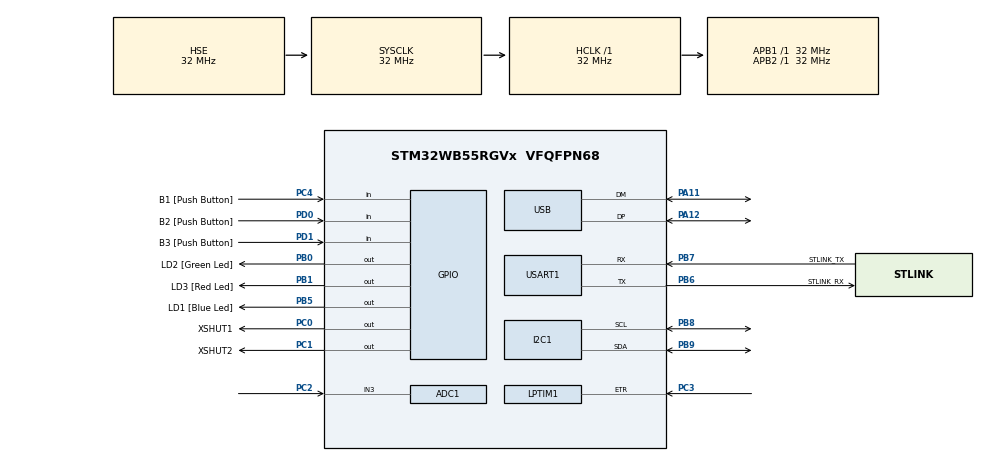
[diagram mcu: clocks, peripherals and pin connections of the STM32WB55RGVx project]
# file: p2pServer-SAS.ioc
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ADC1.Channel-0\#ChannelRegularConversion=ADC_CHANNEL_3
ADC1.Channel-1\#ChannelRegularConversion=ADC_CHANNEL_VREFINT
ADC1.ContinuousConvMode=ENABLE
ADC1.NbrOfConversion=2
ADC1.NbrOfConversionFlag=1
ADC1.OffsetNumber-0\#ChannelRegularConversion=ADC_OFFSET_NONE
ADC1.OffsetNumber-1\#ChannelRegularConversion=ADC_OFFSET_NONE
ADC1.Rank-0\#ChannelRegularConversion=1
ADC1.Rank-1\#ChannelRegularConversion=2
ADC1.SamplingTime-0\#ChannelRegularConversion=ADC_SAMPLETIME_247CYCLES_5
ADC1.SamplingTime-1\#ChannelRegularConversion=ADC_SAMPLETIME_247CYCLES_5
ADC1.master=1
Dma.ADC1.0.Direction=DMA_PERIPH_TO_MEMORY
Dma.ADC1.0.EventEnable=DISABLE
Dma.ADC1.0.Instance=DMA1_Channel1
Dma.ADC1.0.MemDataAlignment=DMA_MDATAALIGN_HALFWORD
Dma.ADC1.0.MemInc=DMA_MINC_ENABLE
Dma.ADC1.0.Mode=DMA_CIRCULAR
Dma.ADC1.0.PeriphDataAlignment=DMA_PDATAALIGN_HALFWORD
Dma.ADC1.0.PeriphInc=DMA_PINC_DISABLE
Dma.ADC1.0.Polarity=HAL_DMAMUX_REQ_GEN_RISING
Dma.ADC1.0.Priority=DMA_PRIORITY_MEDIUM
Dma.ADC1.0.RequestNumber=1
Dma.ADC1.0.SignalID=NONE
Dma.ADC1.0.SyncEnable=DISABLE
Dma.ADC1.0.SyncPolarity=HAL_DMAMUX_SYNC_NO_EVENT
Dma.ADC1.0.SyncRequestNumber=1
Dma.ADC1.0.SyncSignalID=NONE
Dma.Request0=ADC1
Dma.Request1=USART1_TX
Dma.USART1_TX.1.Direction=DMA_MEMORY_TO_PERIPH
Dma.USART1_TX.1.EventEnable=DISABLE
Dma.USART1_TX.1.Instance=DMA2_Channel4
Dma.USART1_TX.1.MemDataAlignment=DMA_MDATAALIGN_BYTE
Dma.USART1_TX.1.MemInc=DMA_MINC_ENABLE
Dma.USART1_TX.1.Mode=DMA_NORMAL
Dma.USART1_TX.1.PeriphDataAlignment=DMA_PDATAALIGN_BYTE
Dma.USART1_TX.1.PeriphInc=DMA_PINC_DISABLE
Dma.USART1_TX.1.Polarity=HAL_DMAMUX_REQ_GEN_RISING
Dma.USART1_TX.1.Priority=DMA_PRIORITY_LOW
Dma.USART1_TX.1.RequestNumber=1
Dma.USART1_TX.1.SignalID=NONE
Dma.USART1_TX.1.SyncEnable=DISABLE
Dma.USART1_TX.1.SyncPolarity=HAL_DMAMUX_SYNC_NO_EVENT
Dma.USART1_TX.1.SyncRequestNumber=1
Dma.USART1_TX.1.SyncSignalID=NONE
I2C1.Timing=0x00707CBB
LPTIM1.ClockPrescaler=LPTIM_PRESCALER_DIV128
Mcu.Family=STM32WB
Mcu.Name=STM32WB55RGVx
Mcu.Package=VFQFPN68
NVIC.ADC1_IRQn=true\:0\:0\:false\:false\:true\:true\:true
NVIC.DMA1_Channel1_IRQn=true\:0\:0\:false\:false\:true\:false\:true
NVIC.DMA2_Channel4_IRQn=true\:0\:0\:false\:false\:true\:false\:true
NVIC.HSEM_IRQn=true\:0\:0\:false\:false\:true\:false\:true
NVIC.LPTIM1_IRQn=true\:0\:0\:false\:false\:true\:true\:true
NVIC.PriorityGroup=NVIC_PRIORITYGROUP_4
NVIC.TIM1_UP_TIM16_IRQn=true\:0\:0\:false\:false\:true\:true\:true
NVIC.USB_LP_IRQn=true\:0\:0\:false\:false\:true\:false\:true
OSC_IN.Mode=HSE-External-Oscillator
OSC_IN.Signal=RCC_OSC_IN
OSC_OUT.Mode=HSE-External-Oscillator
OSC_OUT.Signal=RCC_OSC_OUT
PA11.Mode=Device
PA11.Signal=USB_DM
PA12.Mode=Device
PA12.Signal=USB_DP
PA13.GPIO_Label=JTMS
PA13.Mode=Trace_Asynchronous_SW
PA13.Signal=SYS_JTMS-SWDIO
PA14.GPIO_Label=JTCK
PA14.Mode=Trace_Asynchronous_SW
PA14.Signal=SYS_JTCK-SWCLK
PB0.GPIO_Label=LD2 [Green Led]
PB0.Signal=GPIO_Output
PB1.GPIO_Label=LD3 [Red Led]
PB1.Signal=GPIO_Output
PB3.GPIO_Label=JTDO
PB3.Mode=Trace_Asynchronous_SW
PB3.Signal=SYS_JTDO-SWO
PB5.GPIO_Label=LD1 [Blue Led]
PB5.Signal=GPIO_Output
PB6.GPIO_Label=STLINK_RX
PB6.GPIO_PuPd=GPIO_PULLUP
PB6.Mode=Asynchronous
PB6.Signal=USART1_TX
PB7.GPIO_Label=STLINK_TX
PB7.GPIO_PuPd=GPIO_PULLUP
PB7.Mode=Asynchronous
PB7.Signal=USART1_RX
PB8.Mode=I2C
PB8.Signal=I2C1_SCL
PB9.Mode=I2C
PB9.Signal=I2C1_SDA
PC0.GPIO_Label=XSHUT1
PC0.Signal=GPIO_Output
PC1.GPIO_Label=XSHUT2
PC1.Signal=GPIO_Output
PC13.Mode=SYS_WakeUp1
PC13.Signal=SYS_WKUP2
PC14-OSC32_IN.Mode=LSE-External-Oscillator
PC14-OSC32_IN.Signal=RCC_OSC32_IN
PC15-OSC32_OUT.Mode=LSE-External-Oscillator
PC15-OSC32_OUT.Signal=RCC_OSC32_OUT
PC2.Signal=ADCx_IN3
PC3.Mode=ExternalTrigger
PC3.Signal=LPTIM1_ETR
PC4.GPIO_Label=B1 [Push Button]
PC4.Signal=GPIO_Input
PD0.GPIO_Label=B2 [Push Button]
PD0.Signal=GPIO_Input
PD1.GPIO_Label=B3 [Push Button]
PD1.Signal=GPIO_Input
ProjectManager.HeapSize=0x200
ProjectManager.StackSize=0x400
ProjectManager.TargetToolchain=MDK-ARM V5.32
RCC.ADCFreq_Value=12000000
RCC.AHBFreq_Value=32000000
RCC.APB1Freq_Value=32000000
RCC.APB1TimFreq_Value=32000000
RCC.APB2Freq_Value=32000000
RCC.APB2TimFreq_Value=32000000
RCC.APB3Freq_Value=16000000
RCC.CortexFreq_Value=32000000
RCC.HCLKFreq_Value=32000000
RCC.HSE_VALUE=32000000
RCC.HSI48_VALUE=48000000
RCC.HSI_VALUE=16000000
RCC.PLLN=32
RCC.PLLSAI1N=24
RCC.PLLSAI1R=RCC_PLLR_DIV8
RCC.RFWKPClockSelection=RCC_RFWKPCLKSOURCE_LSE
RCC.SMPSCLockSelectionVirtual=RCC_SMPSCLKSOURCE_HSI
RCC.SMPSCLockSelectionVirtualVirtual=RCC_SMPSCLKSOURCE_HSI
RCC.SMPSDivider=1
RCC.SYSCLKFreq_VALUE=32000000
RCC.SYSCLKSource=RCC_SYSCLKSOURCE_HSE
RCC.USBFreq_Value=48000000
RCC.VCOOutputFreq_Value=128000000
RF1.Mode=RF1_Activate
RF1.Signal=RF_RF1
SH.ADCx_IN3.0=ADC1_IN3,IN3-Single-Ended
STM32_WPAN.CFG_DEBUGGER_SUPPORTED=1
STM32_WPAN.CFG_DEBUG_APP_TRACE=1
STM32_WPAN.CFG_DEBUG_BLE_TRACE=1
STM32_WPAN.CFG_DEBUG_TRACE_UART=hw_uart1
STM32_WPAN.CFG_HW_USART1_ENABLED=0
STM32_WPAN.CFG_LPM_SUPPORTED=1
STM32_WPAN.CUSTOM_P2P_SERVER=Enabled
STM32_WPAN.LOCAL_NAME=SAS_v1
STM32_WPAN.LOCAL_NAME_FORMATTED=,'S','A','S','_','v','1'
STM32_WPAN.P2P_SERVER_NUMBER=P2P_SERVER1
TIM1.Period=2000
TIM1.Prescaler=31999
USART1.VirtualMode-Asynchronous=VM_ASYNC
USART1.WordLength=WORDLENGTH_7B
USB_DEVICE.CLASS_NAME_FS=CDC
USB_DEVICE.VirtualMode=Cdc
USB_DEVICE.VirtualModeFS=Cdc_FS
VP_ADC1_Vref_Input.Mode=IN-Vrefint
VP_HSEM_VS_HSEM.Mode=HSEM_Activate
VP_IPCC_VS_IPCC.Mode=IPCC_Activate
VP_LPTIM1_VS_LPTIM_counterModeInternalClock.Mode=Counts__internal_clock_event_00
VP_RTC_VS_RTC_Activate.Mode=RTC_Enabled
VP_SEQUENCER_VS_SEQUENCER.Mode=SEQUENCER_Enabled
VP_STM32_WPAN_VS_BLE_HOST.Mode=STM32_WPAN_Enabled
VP_TIM1_VS_ClockSourceINT.Mode=Internal
VP_TINY_LPM_VS_TINY_LPM.Mode=TINY_LPM_Enabled
VP_USB_DEVICE_VS_USB_DEVICE_CDC_FS.Mode=CDC_FS
board=NUCLEO-WB55RG

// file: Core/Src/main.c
/* USER CODE BEGIN Header */
/**
  ******************************************************************************
  * @file           : main.c
  * @brief          : Main program body
  ******************************************************************************
  * @attention
  *
  * <h2><center>&copy; Copyright (c) 2021 STMicroelectronics.
  * All rights reserved.</center></h2>
  *
  * This software component is licensed by ST under Ultimate Liberty license
  * SLA0044, the "License"; You may not use this file except in compliance with
  * the License. You may obtain a copy of the License at:
  *                             www.st.com/SLA0044
  *
  ******************************************************************************
  */
/* USER CODE END Header */
#include "main.h"
#include "usb_device.h"

/* USER CODE BEGIN Includes */
#include "stm32_seq.h"
/* USER CODE END Includes */

ADC_HandleTypeDef hadc1;
DMA_HandleTypeDef hdma_adc1;

I2C_HandleTypeDef hi2c1;

IPCC_HandleTypeDef hipcc;

LPTIM_HandleTypeDef hlptim1;

RTC_HandleTypeDef hrtc;

TIM_HandleTypeDef htim1;

UART_HandleTypeDef huart1;
DMA_HandleTypeDef hdma_usart1_tx;

/* USER CODE BEGIN PV */
volatile uint8_t DMA_flag = 0;
volatile float battery_voltage = 0;
volatile float mcu_voltage = 0;
uint32_t ADC_buffer[2] = {0,};
/* USER CODE END PV */

void SystemClock_Config(void);
static void MX_GPIO_Init(void);
static void MX_I2C1_Init(void);
static void MX_IPCC_Init(void);
static void MX_RF_Init(void);
static void MX_RTC_Init(void);
static void MX_USART1_UART_Init(void);
static void MX_DMA_Init(void);
static void MX_ADC1_Init(void);
static void MX_TIM1_Init(void);
static void MX_LPTIM1_Init(void);

int main(void)
{

  /* MCU Configuration--------------------------------------------------------*/

  /* Reset of all peripherals, Initializes the Flash interface and the Systick. */
  HAL_Init();
  /* Config code for STM32_WPAN (HSE Tuning must be done before system clock configuration) */
  MX_APPE_Config();

  /* Configure the system clock */
  SystemClock_Config();

  /* IPCC initialisation */
   MX_IPCC_Init();

  /* Initialize all configured peripherals */
  MX_GPIO_Init();
  MX_I2C1_Init();
  MX_RF_Init();
  MX_RTC_Init();
  MX_USART1_UART_Init();
  MX_DMA_Init();
  MX_ADC1_Init();
  MX_TIM1_Init();
  MX_USB_Device_Init();
  MX_LPTIM1_Init();

  /* Init code for STM32_WPAN */
  MX_APPE_Init();
  /* Infinite loop */
  while (1)
  {
    MX_APPE_Process();

  }
}

void SystemClock_Config(void)
{
  RCC_OscInitTypeDef RCC_OscInitStruct = {0};
  RCC_ClkInitTypeDef RCC_ClkInitStruct = {0};
  RCC_PeriphCLKInitTypeDef PeriphClkInitStruct = {0};

  /** Macro to configure the PLL multiplication factor
  */
  __HAL_RCC_PLL_PLLM_CONFIG(RCC_PLLM_DIV1);
  /** Macro to configure the PLL clock source
  */
  __HAL_RCC_PLL_PLLSOURCE_CONFIG(RCC_PLLSOURCE_MSI);
  /** Configure LSE Drive Capability
  */
  HAL_PWR_EnableBkUpAccess();
  __HAL_RCC_LSEDRIVE_CONFIG(RCC_LSEDRIVE_LOW);
  /** Configure the main internal regulator output voltage
  */
  __HAL_PWR_VOLTAGESCALING_CONFIG(PWR_REGULATOR_VOLTAGE_SCALE1);
  /** Initializes the RCC Oscillators according to the specified parameters
  * in the RCC_OscInitTypeDef structure.
  */
  RCC_OscInitStruct.OscillatorType = RCC_OSCILLATORTYPE_HSI|RCC_OSCILLATORTYPE_LSI1
                              |RCC_OSCILLATORTYPE_HSE|RCC_OSCILLATORTYPE_LSE
                              |RCC_OSCILLATORTYPE_MSI;
  RCC_OscInitStruct.HSEState = RCC_HSE_ON;
  RCC_OscInitStruct.LSEState = RCC_LSE_ON;
  RCC_OscInitStruct.HSIState = RCC_HSI_ON;
  RCC_OscInitStruct.MSIState = RCC_MSI_ON;
  RCC_OscInitStruct.HSICalibrationValue = RCC_HSICALIBRATION_DEFAULT;
  RCC_OscInitStruct.MSICalibrationValue = RCC_MSICALIBRATION_DEFAULT;
  RCC_OscInitStruct.MSIClockRange = RCC_MSIRANGE_6;
  RCC_OscInitStruct.LSIState = RCC_LSI_ON;
  RCC_OscInitStruct.PLL.PLLState = RCC_PLL_NONE;
  if (HAL_RCC_OscConfig(&RCC_OscInitStruct) != HAL_OK)
  {
    Error_Handler();
  }
  /** Configure the SYSCLKSource, HCLK, PCLK1 and PCLK2 clocks dividers
  */
  RCC_ClkInitStruct.ClockType = RCC_CLOCKTYPE_HCLK4|RCC_CLOCKTYPE_HCLK2
                              |RCC_CLOCKTYPE_HCLK|RCC_CLOCKTYPE_SYSCLK
                              |RCC_CLOCKTYPE_PCLK1|RCC_CLOCKTYPE_PCLK2;
  RCC_ClkInitStruct.SYSCLKSource = RCC_SYSCLKSOURCE_HSE;
  RCC_ClkInitStruct.AHBCLKDivider = RCC_SYSCLK_DIV1;
  RCC_ClkInitStruct.APB1CLKDivider = RCC_HCLK_DIV1;
  RCC_ClkInitStruct.APB2CLKDivider = RCC_HCLK_DIV1;
  RCC_ClkInitStruct.AHBCLK2Divider = RCC_SYSCLK_DIV1;
  RCC_ClkInitStruct.AHBCLK4Divider = RCC_SYSCLK_DIV1;

  if (HAL_RCC_ClockConfig(&RCC_ClkInitStruct, FLASH_LATENCY_1) != HAL_OK)
  {
    Error_Handler();
  }
  /** Initializes the peripherals clocks
  */
  PeriphClkInitStruct.PeriphClockSelection = RCC_PERIPHCLK_SMPS|RCC_PERIPHCLK_RFWAKEUP
                              |RCC_PERIPHCLK_RTC|RCC_PERIPHCLK_USART1
                              |RCC_PERIPHCLK_LPTIM1|RCC_PERIPHCLK_I2C1
                              |RCC_PERIPHCLK_USB|RCC_PERIPHCLK_ADC;
  PeriphClkInitStruct.PLLSAI1.PLLN = 24;
  PeriphClkInitStruct.PLLSAI1.PLLP = RCC_PLLP_DIV2;
  PeriphClkInitStruct.PLLSAI1.PLLQ = RCC_PLLQ_DIV2;
  PeriphClkInitStruct.PLLSAI1.PLLR = RCC_PLLR_DIV8;
  PeriphClkInitStruct.PLLSAI1.PLLSAI1ClockOut = RCC_PLLSAI1_USBCLK|RCC_PLLSAI1_ADCCLK;
  PeriphClkInitStruct.Usart1ClockSelection = RCC_USART1CLKSOURCE_PCLK2;
  PeriphClkInitStruct.I2c1ClockSelection = RCC_I2C1CLKSOURCE_PCLK1;
  PeriphClkInitStruct.Lptim1ClockSelection = RCC_LPTIM1CLKSOURCE_PCLK1;
  PeriphClkInitStruct.UsbClockSelection = RCC_USBCLKSOURCE_PLLSAI1;
  PeriphClkInitStruct.AdcClockSelection = RCC_ADCCLKSOURCE_PLLSAI1;
  PeriphClkInitStruct.RTCClockSelection = RCC_RTCCLKSOURCE_LSI;
  PeriphClkInitStruct.RFWakeUpClockSelection = RCC_RFWKPCLKSOURCE_LSE;
  PeriphClkInitStruct.SmpsClockSelection = RCC_SMPSCLKSOURCE_HSI;
  PeriphClkInitStruct.SmpsDivSelection = RCC_SMPSCLKDIV_RANGE0;
  if (HAL_RCCEx_PeriphCLKConfig(&PeriphClkInitStruct) != HAL_OK)
  {
    Error_Handler();
  }
  /** Enable MSI Auto calibration
  */
  HAL_RCCEx_EnableMSIPLLMode();
}

static void MX_ADC1_Init(void)
{

  ADC_ChannelConfTypeDef sConfig = {0};

  /** Common config
  */
  hadc1.Instance = ADC1;
  hadc1.Init.ClockPrescaler = ADC_CLOCK_ASYNC_DIV1;
  hadc1.Init.Resolution = ADC_RESOLUTION_12B;
  hadc1.Init.DataAlign = ADC_DATAALIGN_RIGHT;
  hadc1.Init.ScanConvMode = ADC_SCAN_ENABLE;
  hadc1.Init.EOCSelection = ADC_EOC_SINGLE_CONV;
  hadc1.Init.LowPowerAutoWait = DISABLE;
  hadc1.Init.ContinuousConvMode = ENABLE;
  hadc1.Init.NbrOfConversion = 2;
  hadc1.Init.DiscontinuousConvMode = DISABLE;
  hadc1.Init.ExternalTrigConv = ADC_SOFTWARE_START;
  hadc1.Init.ExternalTrigConvEdge = ADC_EXTERNALTRIGCONVEDGE_NONE;
  hadc1.Init.DMAContinuousRequests = DISABLE;
  hadc1.Init.Overrun = ADC_OVR_DATA_PRESERVED;
  hadc1.Init.OversamplingMode = DISABLE;
  if (HAL_ADC_Init(&hadc1) != HAL_OK)
  {
    Error_Handler();
  }
  /** Configure Regular Channel
  */
  sConfig.Channel = ADC_CHANNEL_3;
  sConfig.Rank = ADC_REGULAR_RANK_1;
  sConfig.SamplingTime = ADC_SAMPLETIME_247CYCLES_5;
  sConfig.SingleDiff = ADC_SINGLE_ENDED;
  sConfig.OffsetNumber = ADC_OFFSET_NONE;
  sConfig.Offset = 0;
  if (HAL_ADC_ConfigChannel(&hadc1, &sConfig) != HAL_OK)
  {
    Error_Handler();
  }
  /** Configure Regular Channel
  */
  sConfig.Channel = ADC_CHANNEL_VREFINT;
  sConfig.Rank = ADC_REGULAR_RANK_2;
  if (HAL_ADC_ConfigChannel(&hadc1, &sConfig) != HAL_OK)
  {
    Error_Handler();
  }

}

static void MX_I2C1_Init(void)
{

  hi2c1.Instance = I2C1;
  hi2c1.Init.Timing = 0x00707CBB;
  hi2c1.Init.OwnAddress1 = 0;
  hi2c1.Init.AddressingMode = I2C_ADDRESSINGMODE_7BIT;
  hi2c1.Init.DualAddressMode = I2C_DUALADDRESS_DISABLE;
  hi2c1.Init.OwnAddress2 = 0;
  hi2c1.Init.OwnAddress2Masks = I2C_OA2_NOMASK;
  hi2c1.Init.GeneralCallMode = I2C_GENERALCALL_DISABLE;
  hi2c1.Init.NoStretchMode = I2C_NOSTRETCH_DISABLE;
  if (HAL_I2C_Init(&hi2c1) != HAL_OK)
  {
    Error_Handler();
  }
  /** Configure Analogue filter
  */
  if (HAL_I2CEx_ConfigAnalogFilter(&hi2c1, I2C_ANALOGFILTER_ENABLE) != HAL_OK)
  {
    Error_Handler();
  }
  /** Configure Digital filter
  */
  if (HAL_I2CEx_ConfigDigitalFilter(&hi2c1, 0) != HAL_OK)
  {
    Error_Handler();
  }

}

static void MX_IPCC_Init(void)
{

  hipcc.Instance = IPCC;
  if (HAL_IPCC_Init(&hipcc) != HAL_OK)
  {
    Error_Handler();
  }

}

static void MX_LPTIM1_Init(void)
{

  hlptim1.Instance = LPTIM1;
  hlptim1.Init.Clock.Source = LPTIM_CLOCKSOURCE_APBCLOCK_LPOSC;
  hlptim1.Init.Clock.Prescaler = LPTIM_PRESCALER_DIV128;
  hlptim1.Init.Trigger.Source = LPTIM_TRIGSOURCE_0;
  hlptim1.Init.Trigger.ActiveEdge = LPTIM_ACTIVEEDGE_RISING;
  hlptim1.Init.Trigger.SampleTime = LPTIM_TRIGSAMPLETIME_DIRECTTRANSITION;
  hlptim1.Init.OutputPolarity = LPTIM_OUTPUTPOLARITY_HIGH;
  hlptim1.Init.UpdateMode = LPTIM_UPDATE_IMMEDIATE;
  hlptim1.Init.CounterSource = LPTIM_COUNTERSOURCE_INTERNAL;
  hlptim1.Init.Input1Source = LPTIM_INPUT1SOURCE_GPIO;
  hlptim1.Init.Input2Source = LPTIM_INPUT2SOURCE_GPIO;
  if (HAL_LPTIM_Init(&hlptim1) != HAL_OK)
  {
    Error_Handler();
  }

}

static void MX_RF_Init(void)
{

}

static void MX_RTC_Init(void)
{

  /** Initialize RTC Only
  */
  hrtc.Instance = RTC;
  hrtc.Init.HourFormat = RTC_HOURFORMAT_24;
  hrtc.Init.AsynchPrediv = CFG_RTC_ASYNCH_PRESCALER;
  hrtc.Init.SynchPrediv = CFG_RTC_SYNCH_PRESCALER;
  hrtc.Init.OutPut = RTC_OUTPUT_DISABLE;
  hrtc.Init.OutPutPolarity = RTC_OUTPUT_POLARITY_HIGH;
  hrtc.Init.OutPutType = RTC_OUTPUT_TYPE_OPENDRAIN;
  hrtc.Init.OutPutRemap = RTC_OUTPUT_REMAP_NONE;
  if (HAL_RTC_Init(&hrtc) != HAL_OK)
  {
    Error_Handler();
  }

}

static void MX_TIM1_Init(void)
{

  TIM_ClockConfigTypeDef sClockSourceConfig = {0};
  TIM_MasterConfigTypeDef sMasterConfig = {0};

  htim1.Instance = TIM1;
  htim1.Init.Prescaler = 31999;
  htim1.Init.CounterMode = TIM_COUNTERMODE_UP;
  htim1.Init.Period = 2000;
  htim1.Init.ClockDivision = TIM_CLOCKDIVISION_DIV1;
  htim1.Init.RepetitionCounter = 0;
  htim1.Init.AutoReloadPreload = TIM_AUTORELOAD_PRELOAD_DISABLE;
  if (HAL_TIM_Base_Init(&htim1) != HAL_OK)
  {
    Error_Handler();
  }
  sClockSourceConfig.ClockSource = TIM_CLOCKSOURCE_INTERNAL;
  if (HAL_TIM_ConfigClockSource(&htim1, &sClockSourceConfig) != HAL_OK)
  {
    Error_Handler();
  }
  sMasterConfig.MasterOutputTrigger = TIM_TRGO_RESET;
  sMasterConfig.MasterOutputTrigger2 = TIM_TRGO2_RESET;
  sMasterConfig.MasterSlaveMode = TIM_MASTERSLAVEMODE_DISABLE;
  if (HAL_TIMEx_MasterConfigSynchronization(&htim1, &sMasterConfig) != HAL_OK)
  {
    Error_Handler();
  }

}

static void MX_USART1_UART_Init(void)
{

  huart1.Instance = USART1;
  huart1.Init.BaudRate = 115200;
  huart1.Init.WordLength = UART_WORDLENGTH_7B;
  huart1.Init.StopBits = UART_STOPBITS_1;
  huart1.Init.Parity = UART_PARITY_NONE;
  huart1.Init.Mode = UART_MODE_TX_RX;
  huart1.Init.HwFlowCtl = UART_HWCONTROL_NONE;
  huart1.Init.OverSampling = UART_OVERSAMPLING_16;
  huart1.Init.OneBitSampling = UART_ONE_BIT_SAMPLE_DISABLE;
  huart1.Init.ClockPrescaler = UART_PRESCALER_DIV1;
  huart1.AdvancedInit.AdvFeatureInit = UART_ADVFEATURE_NO_INIT;
  if (HAL_UART_Init(&huart1) != HAL_OK)
  {
    Error_Handler();
  }
  if (HAL_UARTEx_SetTxFifoThreshold(&huart1, UART_TXFIFO_THRESHOLD_1_8) != HAL_OK)
  {
    Error_Handler();
  }
  if (HAL_UARTEx_SetRxFifoThreshold(&huart1, UART_RXFIFO_THRESHOLD_1_8) != HAL_OK)
  {
    Error_Handler();
  }
  if (HAL_UARTEx_DisableFifoMode(&huart1) != HAL_OK)
  {
    Error_Handler();
  }

}

static void MX_DMA_Init(void)
{

  /* DMA controller clock enable */
  __HAL_RCC_DMAMUX1_CLK_ENABLE();
  __HAL_RCC_DMA1_CLK_ENABLE();
  __HAL_RCC_DMA2_CLK_ENABLE();

  /* DMA interrupt init */
  /* DMA1_Channel1_IRQn interrupt configuration */
  HAL_NVIC_SetPriority(DMA1_Channel1_IRQn, 0, 0);
  HAL_NVIC_EnableIRQ(DMA1_Channel1_IRQn);
  /* DMA2_Channel4_IRQn interrupt configuration */
  HAL_NVIC_SetPriority(DMA2_Channel4_IRQn, 0, 0);
  HAL_NVIC_EnableIRQ(DMA2_Channel4_IRQn);

}

static void MX_GPIO_Init(void)
{
  GPIO_InitTypeDef GPIO_InitStruct = {0};

  /* GPIO Ports Clock Enable */
  __HAL_RCC_GPIOC_CLK_ENABLE();
  __HAL_RCC_GPIOH_CLK_ENABLE();
  __HAL_RCC_GPIOB_CLK_ENABLE();
  __HAL_RCC_GPIOA_CLK_ENABLE();
  __HAL_RCC_GPIOE_CLK_ENABLE();
  __HAL_RCC_GPIOD_CLK_ENABLE();

  /*Configure GPIO pin Output Level */
  HAL_GPIO_WritePin(GPIOC, XSHUT1_Pin|XSHUT2_Pin, GPIO_PIN_RESET);

  /*Configure GPIO pin Output Level */
  HAL_GPIO_WritePin(GPIOB, LD2_Pin|LD3_Pin|LD1_Pin, GPIO_PIN_RESET);

  /*Configure GPIO pin : PH3 */
  GPIO_InitStruct.Pin = GPIO_PIN_3;
  GPIO_InitStruct.Mode = GPIO_MODE_ANALOG;
  GPIO_InitStruct.Pull = GPIO_NOPULL;
  HAL_GPIO_Init(GPIOH, &GPIO_InitStruct);

  /*Configure GPIO pins : XSHUT1_Pin XSHUT2_Pin */
  GPIO_InitStruct.Pin = XSHUT1_Pin|XSHUT2_Pin;
  GPIO_InitStruct.Mode = GPIO_MODE_OUTPUT_PP;
  GPIO_InitStruct.Pull = GPIO_NOPULL;
  GPIO_InitStruct.Speed = GPIO_SPEED_FREQ_LOW;
  HAL_GPIO_Init(GPIOC, &GPIO_InitStruct);

  /*Configure GPIO pins : PA0 PA1 PA2 PA3
                           PA4 PA5 PA6 PA7
                           PA8 PA9 PA10 PA15 */
  GPIO_InitStruct.Pin = GPIO_PIN_0|GPIO_PIN_1|GPIO_PIN_2|GPIO_PIN_3
                          |GPIO_PIN_4|GPIO_PIN_5|GPIO_PIN_6|GPIO_PIN_7
                          |GPIO_PIN_8|GPIO_PIN_9|GPIO_PIN_10|GPIO_PIN_15;
  GPIO_InitStruct.Mode = GPIO_MODE_ANALOG;
  GPIO_InitStruct.Pull = GPIO_NOPULL;
  HAL_GPIO_Init(GPIOA, &GPIO_InitStruct);

  /*Configure GPIO pin : B1_Pin */
  GPIO_InitStruct.Pin = B1_Pin;
  GPIO_InitStruct.Mode = GPIO_MODE_INPUT;
  GPIO_InitStruct.Pull = GPIO_NOPULL;
  HAL_GPIO_Init(B1_GPIO_Port, &GPIO_InitStruct);

  /*Configure GPIO pins : PC5 PC6 PC10 PC11
                           PC12 */
  GPIO_InitStruct.Pin = GPIO_PIN_5|GPIO_PIN_6|GPIO_PIN_10|GPIO_PIN_11
                          |GPIO_PIN_12;
  GPIO_InitStruct.Mode = GPIO_MODE_ANALOG;
  GPIO_InitStruct.Pull = GPIO_NOPULL;
  HAL_GPIO_Init(GPIOC, &GPIO_InitStruct);

  /*Configure GPIO pins : PB2 PB10 PB11 PB12
                           PB13 PB14 PB15 PB4 */
  GPIO_InitStruct.Pin = GPIO_PIN_2|GPIO_PIN_10|GPIO_PIN_11|GPIO_PIN_12
                          |GPIO_PIN_13|GPIO_PIN_14|GPIO_PIN_15|GPIO_PIN_4;
  GPIO_InitStruct.Mode = GPIO_MODE_ANALOG;
  GPIO_InitStruct.Pull = GPIO_NOPULL;
  HAL_GPIO_Init(GPIOB, &GPIO_InitStruct);

  /*Configure GPIO pins : LD2_Pin LD3_Pin LD1_Pin */
  GPIO_InitStruct.Pin = LD2_Pin|LD3_Pin|LD1_Pin;
  GPIO_InitStruct.Mode = GPIO_MODE_OUTPUT_PP;
  GPIO_InitStruct.Pull = GPIO_NOPULL;
  GPIO_InitStruct.Speed = GPIO_SPEED_FREQ_LOW;
  HAL_GPIO_Init(GPIOB, &GPIO_InitStruct);

  /*Configure GPIO pin : PE4 */
  GPIO_InitStruct.Pin = GPIO_PIN_4;
  GPIO_InitStruct.Mode = GPIO_MODE_ANALOG;
  GPIO_InitStruct.Pull = GPIO_NOPULL;
  HAL_GPIO_Init(GPIOE, &GPIO_InitStruct);

  /*Configure GPIO pins : B2_Pin B3_Pin */
  GPIO_InitStruct.Pin = B2_Pin|B3_Pin;
  GPIO_InitStruct.Mode = GPIO_MODE_INPUT;
  GPIO_InitStruct.Pull = GPIO_NOPULL;
  HAL_GPIO_Init(GPIOD, &GPIO_InitStruct);

}

void Error_Handler(void)
{
  __disable_irq();
  while (1)
  {
  }
}

/************************ (C) COPYRIGHT STMicroelectronics *****END OF FILE****/
